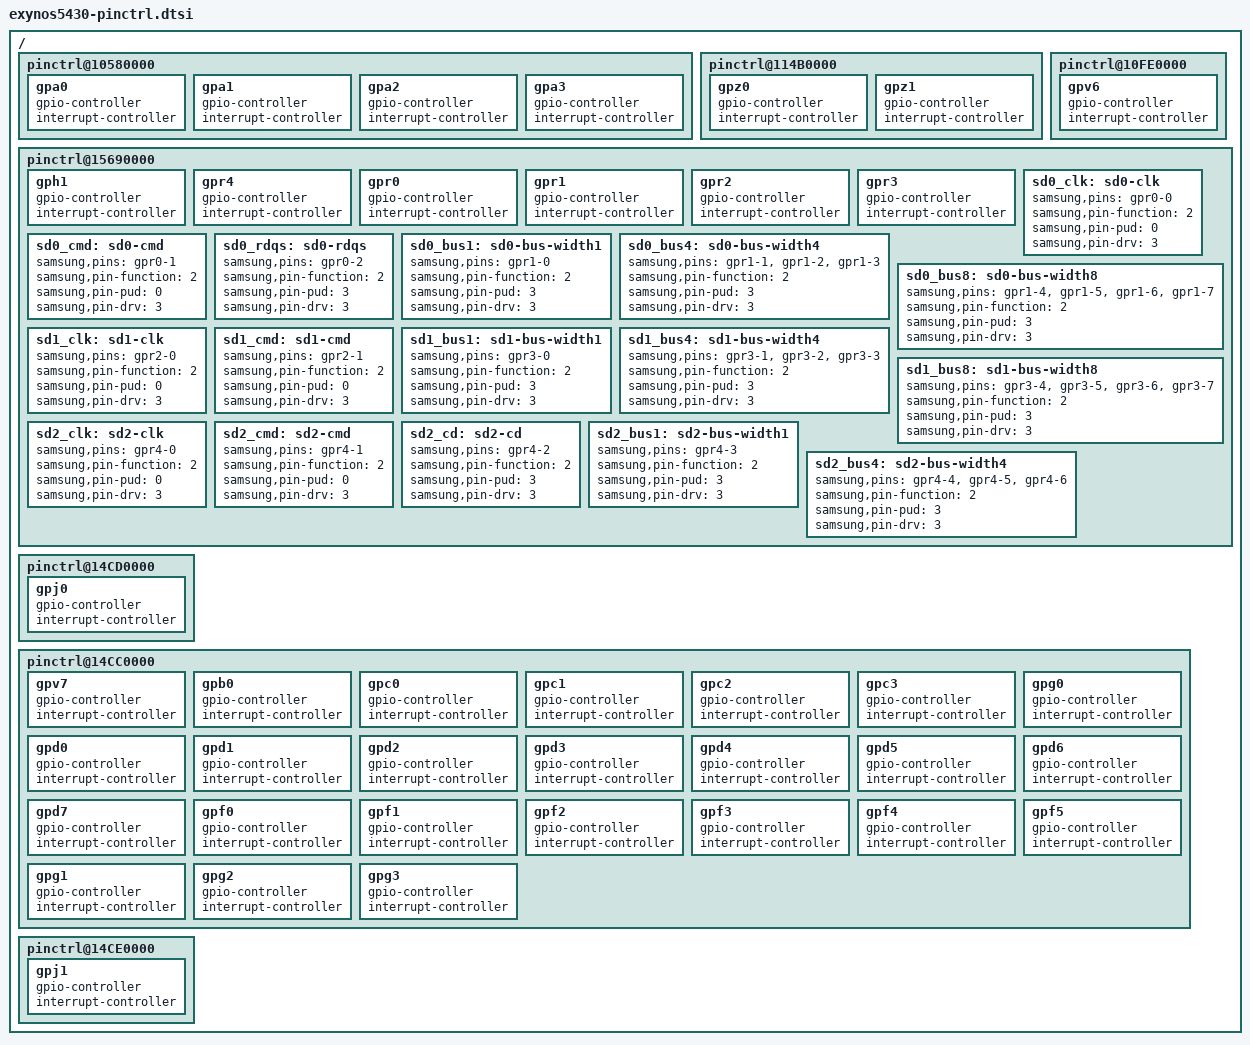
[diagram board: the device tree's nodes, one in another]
/*
 * Samsung's Exynos5430 SoC pin-mux and pin-config device tree source
 *
 * Copyright (c) 2013 Samsung Electronics Co., Ltd.
 *		http://www.samsung.com
 *
 * Samsung's Exynos5430 SoC pin-mux and pin-config options are listed as device
 * tree nodes are listed in this file.
 *
 * This program is free software; you can redistribute it and/or modify
 * it under the terms of the GNU General Public License version 2 as
 * published by the Free Software Foundation.
*/

/ {
	pinctrl@10580000 {
		gpa0: gpa0 {
			gpio-controller;
			#gpio-cells = <2>;

			interrupt-controller;
			#interrupt-cells = <2>;
		};

		gpa1: gpa1 {
			gpio-controller;
			#gpio-cells = <2>;

			interrupt-controller;
			#interrupt-cells = <2>;
		};

		gpa2: gpa2 {
			gpio-controller;
			#gpio-cells = <2>;

			interrupt-controller;
			#interrupt-cells = <2>;
		};

		gpa3: gpa3 {
			gpio-controller;
			#gpio-cells = <2>;

			interrupt-controller;
			#interrupt-cells = <2>;
		};
	};

	pinctrl@114B0000 {
		gpz0: gpz0 {
			gpio-controller;
			#gpio-cells = <2>;

			interrupt-controller;
			#interrupt-cells = <2>;
		};

		gpz1: gpz1 {
			gpio-controller;
			#gpio-cells = <2>;

			interrupt-controller;
			#interrupt-cells = <2>;
		};
	};

	pinctrl@10FE0000 {
		gpv6: gpv6 {
			gpio-controller;
			#gpio-cells = <2>;

			interrupt-controller;
			#interrupt-cells = <2>;
		};
	};

	pinctrl@15690000 {
		gph1: gph1 {
			gpio-controller;
			#gpio-cells = <2>;

			interrupt-controller;
			#interrupt-cells = <2>;
		};

		gpr4: gpr4 {
			gpio-controller;
			#gpio-cells = <2>;

			interrupt-controller;
			#interrupt-cells = <2>;
		};

		gpr0: gpr0 {
			gpio-controller;
			#gpio-cells = <2>;

			interrupt-controller;
			#interrupt-cells = <2>;
		};

		gpr1: gpr1 {
			gpio-controller;
			#gpio-cells = <2>;

			interrupt-controller;
			#interrupt-cells = <2>;
		};

		gpr2: gpr2 {
			gpio-controller;
			#gpio-cells = <2>;

			interrupt-controller;
			#interrupt-cells = <2>;
		};

		gpr3: gpr3 {
			gpio-controller;
			#gpio-cells = <2>;

			interrupt-controller;
			#interrupt-cells = <2>;
		};

		sd0_clk: sd0-clk {
			samsung,pins = "gpr0-0";
			samsung,pin-function = <2>;
			samsung,pin-pud = <0>;
			samsung,pin-drv = <3>;
		};

		sd0_cmd: sd0-cmd {
			samsung,pins = "gpr0-1";
			samsung,pin-function = <2>;
			samsung,pin-pud = <0>;
			samsung,pin-drv = <3>;
		};

		sd0_rdqs: sd0-rdqs {
			samsung,pins = "gpr0-2";
			samsung,pin-function = <2>;
			samsung,pin-pud = <3>;
			samsung,pin-drv = <3>;
		};

		sd0_bus1: sd0-bus-width1 {
			samsung,pins = "gpr1-0";
			samsung,pin-function = <2>;
			samsung,pin-pud = <3>;
			samsung,pin-drv = <3>;
		};

		sd0_bus4: sd0-bus-width4 {
			samsung,pins = "gpr1-1", "gpr1-2", "gpr1-3";
			samsung,pin-function = <2>;
			samsung,pin-pud = <3>;
			samsung,pin-drv = <3>;
		};

		sd0_bus8: sd0-bus-width8 {
			samsung,pins = "gpr1-4", "gpr1-5", "gpr1-6", "gpr1-7";
			samsung,pin-function = <2>;
			samsung,pin-pud = <3>;
			samsung,pin-drv = <3>;
		};

		sd1_clk: sd1-clk {
			samsung,pins = "gpr2-0";
			samsung,pin-function = <2>;
			samsung,pin-pud = <0>;
			samsung,pin-drv = <3>;
		};

		sd1_cmd: sd1-cmd {
			samsung,pins = "gpr2-1";
			samsung,pin-function = <2>;
			samsung,pin-pud = <0>;
			samsung,pin-drv = <3>;
		};

		sd1_bus1: sd1-bus-width1 {
			samsung,pins = "gpr3-0";
			samsung,pin-function = <2>;
			samsung,pin-pud = <3>;
			samsung,pin-drv = <3>;
		};

		sd1_bus4: sd1-bus-width4 {
			samsung,pins = "gpr3-1", "gpr3-2", "gpr3-3";
			samsung,pin-function = <2>;
			samsung,pin-pud = <3>;
			samsung,pin-drv = <3>;
		};

		sd1_bus8: sd1-bus-width8 {
			samsung,pins = "gpr3-4", "gpr3-5", "gpr3-6", "gpr3-7";
			samsung,pin-function = <2>;
			samsung,pin-pud = <3>;
			samsung,pin-drv = <3>;
		};

		sd2_clk: sd2-clk {
			samsung,pins = "gpr4-0";
			samsung,pin-function = <2>;
			samsung,pin-pud = <0>;
			samsung,pin-drv = <3>;
		};

		sd2_cmd: sd2-cmd {
			samsung,pins = "gpr4-1";
			samsung,pin-function = <2>;
			samsung,pin-pud = <0>;
			samsung,pin-drv = <3>;
		};

		sd2_cd: sd2-cd {
			samsung,pins = "gpr4-2";
			samsung,pin-function = <2>;
			samsung,pin-pud = <3>;
			samsung,pin-drv = <3>;
		};

		sd2_bus1: sd2-bus-width1 {
			samsung,pins = "gpr4-3";
			samsung,pin-function = <2>;
			samsung,pin-pud = <3>;
			samsung,pin-drv = <3>;
		};

		sd2_bus4: sd2-bus-width4 {
			samsung,pins = "gpr4-4", "gpr4-5", "gpr4-6";
			samsung,pin-function = <2>;
			samsung,pin-pud = <3>;
			samsung,pin-drv = <3>;
		};
	};

	pinctrl@14CD0000 {
		gpj0: gpj0 {
			gpio-controller;
			#gpio-cells = <2>;

			interrupt-controller;
			#interrupt-cells = <2>;
		};
	};

	pinctrl@14CC0000 {
		gpv7: gpv7 {
			gpio-controller;
			#gpio-cells = <2>;

			interrupt-controller;
			#interrupt-cells = <2>;
		};

		gpb0: gpb0 {
			gpio-controller;
			#gpio-cells = <2>;

			interrupt-controller;
			#interrupt-cells = <2>;
		};

		gpc0: gpc0 {
			gpio-controller;
			#gpio-cells = <2>;

			interrupt-controller;
			#interrupt-cells = <2>;
		};

		gpc1: gpc1 {
			gpio-controller;
			#gpio-cells = <2>;

			interrupt-controller;
			#interrupt-cells = <2>;
		};

		gpc2: gpc2 {
			gpio-controller;
			#gpio-cells = <2>;

			interrupt-controller;
			#interrupt-cells = <2>;
		};

		gpc3: gpc3 {
			gpio-controller;
			#gpio-cells = <2>;

			interrupt-controller;
			#interrupt-cells = <2>;
		};

		gpg0: gpg0 {
			gpio-controller;
			#gpio-cells = <2>;

			interrupt-controller;
			#interrupt-cells = <2>;
		};

		gpd0: gpd0 {
			gpio-controller;
			#gpio-cells = <2>;

			interrupt-controller;
			#interrupt-cells = <2>;
		};

		gpd1: gpd1 {
			gpio-controller;
			#gpio-cells = <2>;

			interrupt-controller;
			#interrupt-cells = <2>;
		};

		gpd2: gpd2 {
			gpio-controller;
			#gpio-cells = <2>;

			interrupt-controller;
			#interrupt-cells = <2>;
		};

		gpd3: gpd3 {
			gpio-controller;
			#gpio-cells = <2>;

			interrupt-controller;
			#interrupt-cells = <2>;
		};

		gpd4: gpd4 {
			gpio-controller;
			#gpio-cells = <2>;

			interrupt-controller;
			#interrupt-cells = <2>;
		};

		gpd5: gpd5 {
			gpio-controller;
			#gpio-cells = <2>;

			interrupt-controller;
			#interrupt-cells = <2>;
		};

		gpd6: gpd6 {
			gpio-controller;
			#gpio-cells = <2>;

			interrupt-controller;
			#interrupt-cells = <2>;
		};

		gpd7: gpd7 {
			gpio-controller;
			#gpio-cells = <2>;

			interrupt-controller;
			#interrupt-cells = <2>;
		};

		gpf0: gpf0 {
			gpio-controller;
			#gpio-cells = <2>;

			interrupt-controller;
			#interrupt-cells = <2>;
		};

		gpf1: gpf1 {
			gpio-controller;
			#gpio-cells = <2>;

			interrupt-controller;
			#interrupt-cells = <2>;
		};

		gpf2: gpf2 {
			gpio-controller;
			#gpio-cells = <2>;

			interrupt-controller;
			#interrupt-cells = <2>;
		};

		gpf3: gpf3 {
			gpio-controller;
			#gpio-cells = <2>;

			interrupt-controller;
			#interrupt-cells = <2>;
		};

		gpf4: gpf4 {
			gpio-controller;
			#gpio-cells = <2>;

			interrupt-controller;
			#interrupt-cells = <2>;
		};

		gpf5: gpf5 {
			gpio-controller;
			#gpio-cells = <2>;

			interrupt-controller;
			#interrupt-cells = <2>;
		};

		gpg1: gpg1 {
			gpio-controller;
			#gpio-cells = <2>;

			interrupt-controller;
			#interrupt-cells = <2>;
		};

		gpg2: gpg2 {
			gpio-controller;
			#gpio-cells = <2>;

			interrupt-controller;
			#interrupt-cells = <2>;
		};

		gpg3: gpg3 {
			gpio-controller;
			#gpio-cells = <2>;

			interrupt-controller;
			#interrupt-cells = <2>;
		};
	};

	pinctrl@14CE0000 {
		gpj1: gpj1 {
			gpio-controller;
			#gpio-cells = <2>;

			interrupt-controller;
			#interrupt-cells = <2>;
		};
	};
};

